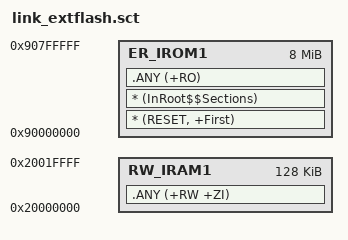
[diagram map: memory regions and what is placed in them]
#! armcc -E
; *************************************************************
; *** Scatter-Loading Description File generated by uVision ***
; *************************************************************

#define m_text_start 0x90000000
#define m_text_size  0x00800000

#define m_data_start 0x20000000
#define m_data_size  0x00020000

LR_IROM1 m_text_start m_text_size           ; load region size_region
{
    ER_IROM1 m_text_start m_text_size       ; load address = execution address
    {  
        * (RESET, +First)
        * (InRoot$$Sections)
        .ANY (+RO)
    }
  
    RW_IRAM1 m_data_start m_data_size       ; RW data
    { 
        .ANY (+RW +ZI)
    }
}
